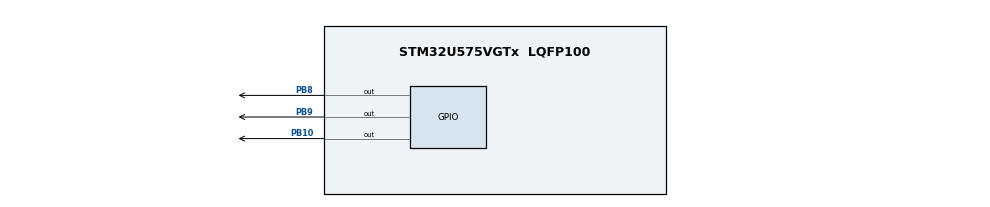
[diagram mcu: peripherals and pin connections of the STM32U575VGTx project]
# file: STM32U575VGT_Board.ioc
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CORTEX_M33_NS.userName=CORTEX_M33
Mcu.Family=STM32U5
Mcu.Name=STM32U575VGTx
Mcu.Package=LQFP100
NVIC.PriorityGroup=NVIC_PRIORITYGROUP_4
PA10.Signal=USART1_RX
PA11.Signal=USB_OTG_FS_DM
PA12.Signal=USB_OTG_FS_DP
PA2.Signal=USART2_TX
PA3.Signal=USART2_RX
PA4.Signal=OCTOSPIM_P1_NCS
PA6.Signal=OCTOSPIM_P1_IO3
PA7.Signal=OCTOSPIM_P1_IO2
PA9.Signal=USART1_TX
PB0.Signal=OCTOSPIM_P1_IO1
PB1.Signal=OCTOSPIM_P1_IO0
PB10.Signal=GPIO_Output
PB3\ (JTDO/TRACESWO).Signal=USART1_RTS
PB4\ (NJTRST).Signal=USART1_CTS
PB6.Signal=I2C1_SCL
PB7.Signal=I2C1_SDA
PB8.Signal=GPIO_Output
PB9.Signal=GPIO_Output
PC0.Signal=LPUART1_RX
PC1.Signal=LPUART1_TX
PC10.Signal=SDMMC1_D2
PC11.Signal=SDMMC1_D3
PC12.Signal=SDMMC1_CK
PC8.Signal=SDMMC1_D0
PC9.Signal=SDMMC1_D1
PD2.Signal=SDMMC1_CMD
PD8.Signal=USART3_TX
PD9.Signal=USART3_RX
PE10.Signal=OCTOSPIM_P1_CLK
PE12.Signal=SPI1_NSS
PE13.Signal=SPI1_SCK
PE14.Signal=SPI1_MISO
PE15.Signal=SPI1_MOSI
ProjectManager.HeapSize=0x200
ProjectManager.StackSize=0x400
ProjectManager.TargetToolchain=STM32CubeIDE
RCC.DACCLockSelectionVirtualString=RCC_DAC1CLKSOURCE_LSI
RCC.SYSCLKSource=RCC_SYSCLKSOURCE_PLLCLK
VP_ICACHE_VS_ENABLE_ICACHE_MEMORY.Mode=Memoryregions
VP_ICACHE_VS_ICACHE.Mode=DefaultMode
board=custom

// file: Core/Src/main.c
/* USER CODE BEGIN Header */
/**
  ******************************************************************************
  * @file           : main.c
  * @brief          : Main program body
  ******************************************************************************
  * @attention
  *
  * Copyright (c) 2024 STMicroelectronics.
  * All rights reserved.
  *
  * This software is licensed under terms that can be found in the LICENSE file
  * in the root directory of this software component.
  * If no LICENSE file comes with this software, it is provided AS-IS.
  *
  ******************************************************************************
  */
/* USER CODE END Header */
#include "main.h"

void SystemClock_Config(void);
static void SystemPower_Config(void);
static void MX_GPIO_Init(void);
static void MX_ICACHE_Init(void);

int main(void)
{

  /* MCU Configuration--------------------------------------------------------*/

  /* Reset of all peripherals, Initializes the Flash interface and the Systick. */
  HAL_Init();

  /* Configure the system clock */
  SystemClock_Config();

  /* Configure the System Power */
  SystemPower_Config();

  /* Initialize all configured peripherals */
  MX_GPIO_Init();
  MX_ICACHE_Init();

  /* Infinite loop */
  /* USER CODE BEGIN WHILE */
  while (1)
  {
	  HAL_Delay(1000);
	  HAL_GPIO_TogglePin(GPIOB, GPIO_PIN_8);
	  HAL_GPIO_TogglePin(GPIOB, GPIO_PIN_9);
	  HAL_GPIO_TogglePin(GPIOB, GPIO_PIN_10);
    /* USER CODE END WHILE */

  }
}

void SystemClock_Config(void)
{
  RCC_OscInitTypeDef RCC_OscInitStruct = {0};
  RCC_ClkInitTypeDef RCC_ClkInitStruct = {0};

  /** Configure the main internal regulator output voltage
  */
  if (HAL_PWREx_ControlVoltageScaling(PWR_REGULATOR_VOLTAGE_SCALE3) != HAL_OK)
  {
    Error_Handler();
  }

  /** Initializes the CPU, AHB and APB buses clocks
  */
  RCC_OscInitStruct.OscillatorType = RCC_OSCILLATORTYPE_MSI;
  RCC_OscInitStruct.MSIState = RCC_MSI_ON;
  RCC_OscInitStruct.MSICalibrationValue = RCC_MSICALIBRATION_DEFAULT;
  RCC_OscInitStruct.MSIClockRange = RCC_MSIRANGE_4;
  RCC_OscInitStruct.PLL.PLLState = RCC_PLL_ON;
  RCC_OscInitStruct.PLL.PLLSource = RCC_PLLSOURCE_MSI;
  RCC_OscInitStruct.PLL.PLLMBOOST = RCC_PLLMBOOST_DIV1;
  RCC_OscInitStruct.PLL.PLLM = 1;
  RCC_OscInitStruct.PLL.PLLN = 129;
  RCC_OscInitStruct.PLL.PLLP = 2;
  RCC_OscInitStruct.PLL.PLLQ = 2;
  RCC_OscInitStruct.PLL.PLLR = 2;
  RCC_OscInitStruct.PLL.PLLRGE = RCC_PLLVCIRANGE_0;
  RCC_OscInitStruct.PLL.PLLFRACN = 0;
  if (HAL_RCC_OscConfig(&RCC_OscInitStruct) != HAL_OK)
  {
    Error_Handler();
  }

  /** Initializes the CPU, AHB and APB buses clocks
  */
  RCC_ClkInitStruct.ClockType = RCC_CLOCKTYPE_HCLK|RCC_CLOCKTYPE_SYSCLK
                              |RCC_CLOCKTYPE_PCLK1|RCC_CLOCKTYPE_PCLK2
                              |RCC_CLOCKTYPE_PCLK3;
  RCC_ClkInitStruct.SYSCLKSource = RCC_SYSCLKSOURCE_PLLCLK;
  RCC_ClkInitStruct.AHBCLKDivider = RCC_SYSCLK_DIV1;
  RCC_ClkInitStruct.APB1CLKDivider = RCC_HCLK_DIV1;
  RCC_ClkInitStruct.APB2CLKDivider = RCC_HCLK_DIV1;
  RCC_ClkInitStruct.APB3CLKDivider = RCC_HCLK_DIV1;

  if (HAL_RCC_ClockConfig(&RCC_ClkInitStruct, FLASH_LATENCY_0) != HAL_OK)
  {
    Error_Handler();
  }
}

/**
  * @brief Power Configuration
  * @retval None
  */
static void SystemPower_Config(void)
{
}

static void MX_ICACHE_Init(void)
{

  ICACHE_RegionConfigTypeDef pRegionConfig = {0};

  /** Configure and enable a region for memory remapping.
  */
  if (HAL_ICACHE_Disable() != HAL_OK)
  {
    Error_Handler();
  }
  pRegionConfig.BaseAddress = 0x0;
  pRegionConfig.RemapAddress = 0x0;
  pRegionConfig.Size = ICACHE_REGIONSIZE_2MB;
  pRegionConfig.TrafficRoute = ICACHE_MASTER1_PORT;
  pRegionConfig.OutputBurstType = ICACHE_OUTPUT_BURST_WRAP;
  if (HAL_ICACHE_EnableRemapRegion(ICACHE_REGION_0, &pRegionConfig) != HAL_OK)
  {
    Error_Handler();
  }

  /** Enable instruction cache (default 2-ways set associative cache)
  */
  if (HAL_ICACHE_Enable() != HAL_OK)
  {
    Error_Handler();
  }

}

static void MX_GPIO_Init(void)
{
  GPIO_InitTypeDef GPIO_InitStruct = {0};

  /* GPIO Ports Clock Enable */
  __HAL_RCC_GPIOC_CLK_ENABLE();
  __HAL_RCC_GPIOA_CLK_ENABLE();
  __HAL_RCC_GPIOB_CLK_ENABLE();
  __HAL_RCC_GPIOE_CLK_ENABLE();
  __HAL_RCC_GPIOD_CLK_ENABLE();

  /*Configure GPIO pin Output Level */
  HAL_GPIO_WritePin(GPIOB, GPIO_PIN_10|GPIO_PIN_8|GPIO_PIN_9, GPIO_PIN_RESET);

  /*Configure GPIO pins : PC0 PC1 */
  GPIO_InitStruct.Pin = GPIO_PIN_0|GPIO_PIN_1;
  GPIO_InitStruct.Mode = GPIO_MODE_AF_PP;
  GPIO_InitStruct.Pull = GPIO_NOPULL;
  GPIO_InitStruct.Speed = GPIO_SPEED_FREQ_LOW;
  GPIO_InitStruct.Alternate = GPIO_AF8_LPUART1;
  HAL_GPIO_Init(GPIOC, &GPIO_InitStruct);

  /*Configure GPIO pins : PA2 PA3 */
  GPIO_InitStruct.Pin = GPIO_PIN_2|GPIO_PIN_3;
  GPIO_InitStruct.Mode = GPIO_MODE_AF_PP;
  GPIO_InitStruct.Pull = GPIO_NOPULL;
  GPIO_InitStruct.Speed = GPIO_SPEED_FREQ_LOW;
  GPIO_InitStruct.Alternate = GPIO_AF7_USART2;
  HAL_GPIO_Init(GPIOA, &GPIO_InitStruct);

  /*Configure GPIO pin : PA4 */
  GPIO_InitStruct.Pin = GPIO_PIN_4;
  GPIO_InitStruct.Mode = GPIO_MODE_AF_PP;
  GPIO_InitStruct.Pull = GPIO_NOPULL;
  GPIO_InitStruct.Speed = GPIO_SPEED_FREQ_VERY_HIGH;
  GPIO_InitStruct.Alternate = GPIO_AF3_OCTOSPI1;
  HAL_GPIO_Init(GPIOA, &GPIO_InitStruct);

  /*Configure GPIO pins : PA6 PA7 */
  GPIO_InitStruct.Pin = GPIO_PIN_6|GPIO_PIN_7;
  GPIO_InitStruct.Mode = GPIO_MODE_AF_PP;
  GPIO_InitStruct.Pull = GPIO_NOPULL;
  GPIO_InitStruct.Speed = GPIO_SPEED_FREQ_VERY_HIGH;
  GPIO_InitStruct.Alternate = GPIO_AF10_OCTOSPI1;
  HAL_GPIO_Init(GPIOA, &GPIO_InitStruct);

  /*Configure GPIO pins : PB0 PB1 */
  GPIO_InitStruct.Pin = GPIO_PIN_0|GPIO_PIN_1;
  GPIO_InitStruct.Mode = GPIO_MODE_AF_PP;
  GPIO_InitStruct.Pull = GPIO_NOPULL;
  GPIO_InitStruct.Speed = GPIO_SPEED_FREQ_VERY_HIGH;
  GPIO_InitStruct.Alternate = GPIO_AF10_OCTOSPI1;
  HAL_GPIO_Init(GPIOB, &GPIO_InitStruct);

  /*Configure GPIO pin : PE10 */
  GPIO_InitStruct.Pin = GPIO_PIN_10;
  GPIO_InitStruct.Mode = GPIO_MODE_AF_PP;
  GPIO_InitStruct.Pull = GPIO_NOPULL;
  GPIO_InitStruct.Speed = GPIO_SPEED_FREQ_VERY_HIGH;
  GPIO_InitStruct.Alternate = GPIO_AF10_OCTOSPI1;
  HAL_GPIO_Init(GPIOE, &GPIO_InitStruct);

  /*Configure GPIO pins : PE12 PE13 PE14 PE15 */
  GPIO_InitStruct.Pin = GPIO_PIN_12|GPIO_PIN_13|GPIO_PIN_14|GPIO_PIN_15;
  GPIO_InitStruct.Mode = GPIO_MODE_AF_PP;
  GPIO_InitStruct.Pull = GPIO_NOPULL;
  GPIO_InitStruct.Speed = GPIO_SPEED_FREQ_LOW;
  GPIO_InitStruct.Alternate = GPIO_AF5_SPI1;
  HAL_GPIO_Init(GPIOE, &GPIO_InitStruct);

  /*Configure GPIO pins : PB10 PB8 PB9 */
  GPIO_InitStruct.Pin = GPIO_PIN_10|GPIO_PIN_8|GPIO_PIN_9;
  GPIO_InitStruct.Mode = GPIO_MODE_OUTPUT_PP;
  GPIO_InitStruct.Pull = GPIO_NOPULL;
  GPIO_InitStruct.Speed = GPIO_SPEED_FREQ_LOW;
  HAL_GPIO_Init(GPIOB, &GPIO_InitStruct);

  /*Configure GPIO pins : PD8 PD9 */
  GPIO_InitStruct.Pin = GPIO_PIN_8|GPIO_PIN_9;
  GPIO_InitStruct.Mode = GPIO_MODE_AF_PP;
  GPIO_InitStruct.Pull = GPIO_NOPULL;
  GPIO_InitStruct.Speed = GPIO_SPEED_FREQ_LOW;
  GPIO_InitStruct.Alternate = GPIO_AF7_USART3;
  HAL_GPIO_Init(GPIOD, &GPIO_InitStruct);

  /*Configure GPIO pins : PC8 PC9 PC10 PC11
                           PC12 */
  GPIO_InitStruct.Pin = GPIO_PIN_8|GPIO_PIN_9|GPIO_PIN_10|GPIO_PIN_11
                          |GPIO_PIN_12;
  GPIO_InitStruct.Mode = GPIO_MODE_AF_PP;
  GPIO_InitStruct.Pull = GPIO_NOPULL;
  GPIO_InitStruct.Speed = GPIO_SPEED_FREQ_HIGH;
  GPIO_InitStruct.Alternate = GPIO_AF12_SDMMC1;
  HAL_GPIO_Init(GPIOC, &GPIO_InitStruct);

  /*Configure GPIO pins : PA9 PA10 */
  GPIO_InitStruct.Pin = GPIO_PIN_9|GPIO_PIN_10;
  GPIO_InitStruct.Mode = GPIO_MODE_AF_PP;
  GPIO_InitStruct.Pull = GPIO_NOPULL;
  GPIO_InitStruct.Speed = GPIO_SPEED_FREQ_LOW;
  GPIO_InitStruct.Alternate = GPIO_AF7_USART1;
  HAL_GPIO_Init(GPIOA, &GPIO_InitStruct);

  /*Configure GPIO pins : PA11 PA12 */
  GPIO_InitStruct.Pin = GPIO_PIN_11|GPIO_PIN_12;
  GPIO_InitStruct.Mode = GPIO_MODE_AF_PP;
  GPIO_InitStruct.Pull = GPIO_NOPULL;
  GPIO_InitStruct.Speed = GPIO_SPEED_FREQ_LOW;
  GPIO_InitStruct.Alternate = GPIO_AF10_USB;
  HAL_GPIO_Init(GPIOA, &GPIO_InitStruct);

  /*Configure GPIO pin : PD2 */
  GPIO_InitStruct.Pin = GPIO_PIN_2;
  GPIO_InitStruct.Mode = GPIO_MODE_AF_PP;
  GPIO_InitStruct.Pull = GPIO_NOPULL;
  GPIO_InitStruct.Speed = GPIO_SPEED_FREQ_HIGH;
  GPIO_InitStruct.Alternate = GPIO_AF12_SDMMC1;
  HAL_GPIO_Init(GPIOD, &GPIO_InitStruct);

  /*Configure GPIO pins : PB3 PB4 */
  GPIO_InitStruct.Pin = GPIO_PIN_3|GPIO_PIN_4;
  GPIO_InitStruct.Mode = GPIO_MODE_AF_PP;
  GPIO_InitStruct.Pull = GPIO_NOPULL;
  GPIO_InitStruct.Speed = GPIO_SPEED_FREQ_LOW;
  GPIO_InitStruct.Alternate = GPIO_AF7_USART1;
  HAL_GPIO_Init(GPIOB, &GPIO_InitStruct);

  /*Configure GPIO pins : PB6 PB7 */
  GPIO_InitStruct.Pin = GPIO_PIN_6|GPIO_PIN_7;
  GPIO_InitStruct.Mode = GPIO_MODE_AF_OD;
  GPIO_InitStruct.Pull = GPIO_NOPULL;
  GPIO_InitStruct.Speed = GPIO_SPEED_FREQ_LOW;
  GPIO_InitStruct.Alternate = GPIO_AF4_I2C1;
  HAL_GPIO_Init(GPIOB, &GPIO_InitStruct);

}

void Error_Handler(void)
{
  /* USER CODE BEGIN Error_Handler_Debug */
  /* User can add his own implementation to report the HAL error return state */
  __disable_irq();
  while (1)
  {
	  HAL_Delay(200);
	  HAL_GPIO_TogglePin(GPIOB, GPIO_PIN_10);
  }
  /* USER CODE END Error_Handler_Debug */
}
